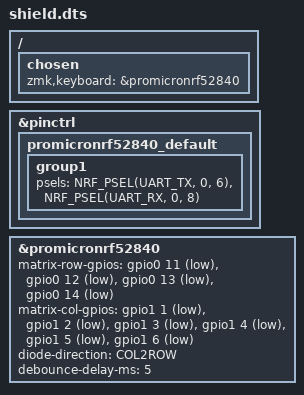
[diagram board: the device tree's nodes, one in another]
/ {
    chosen {
        zmk,keyboard = &promicronrf52840;
    };
};

&pinctrl {
    promicronrf52840_default: promicronrf52840_default {
        group1 {
            psels = <NRF_PSEL(UART_TX, 0, 6)>,
                    <NRF_PSEL(UART_RX, 0, 8)>;
        };
    };
};

&promicronrf52840 {
    matrix-row-gpios = <&gpio0 11 GPIO_ACTIVE_LOW>,
                       <&gpio0 12 GPIO_ACTIVE_LOW>,
                       <&gpio0 13 GPIO_ACTIVE_LOW>,
                       <&gpio0 14 GPIO_ACTIVE_LOW>;
    matrix-col-gpios = <&gpio1 1 GPIO_ACTIVE_LOW>,
                       <&gpio1 2 GPIO_ACTIVE_LOW>,
                       <&gpio1 3 GPIO_ACTIVE_LOW>,
                       <&gpio1 4 GPIO_ACTIVE_LOW>,
                       <&gpio1 5 GPIO_ACTIVE_LOW>,
                       <&gpio1 6 GPIO_ACTIVE_LOW>;

    diode-direction = COL2ROW;
    debounce-delay-ms = <5>;
};
